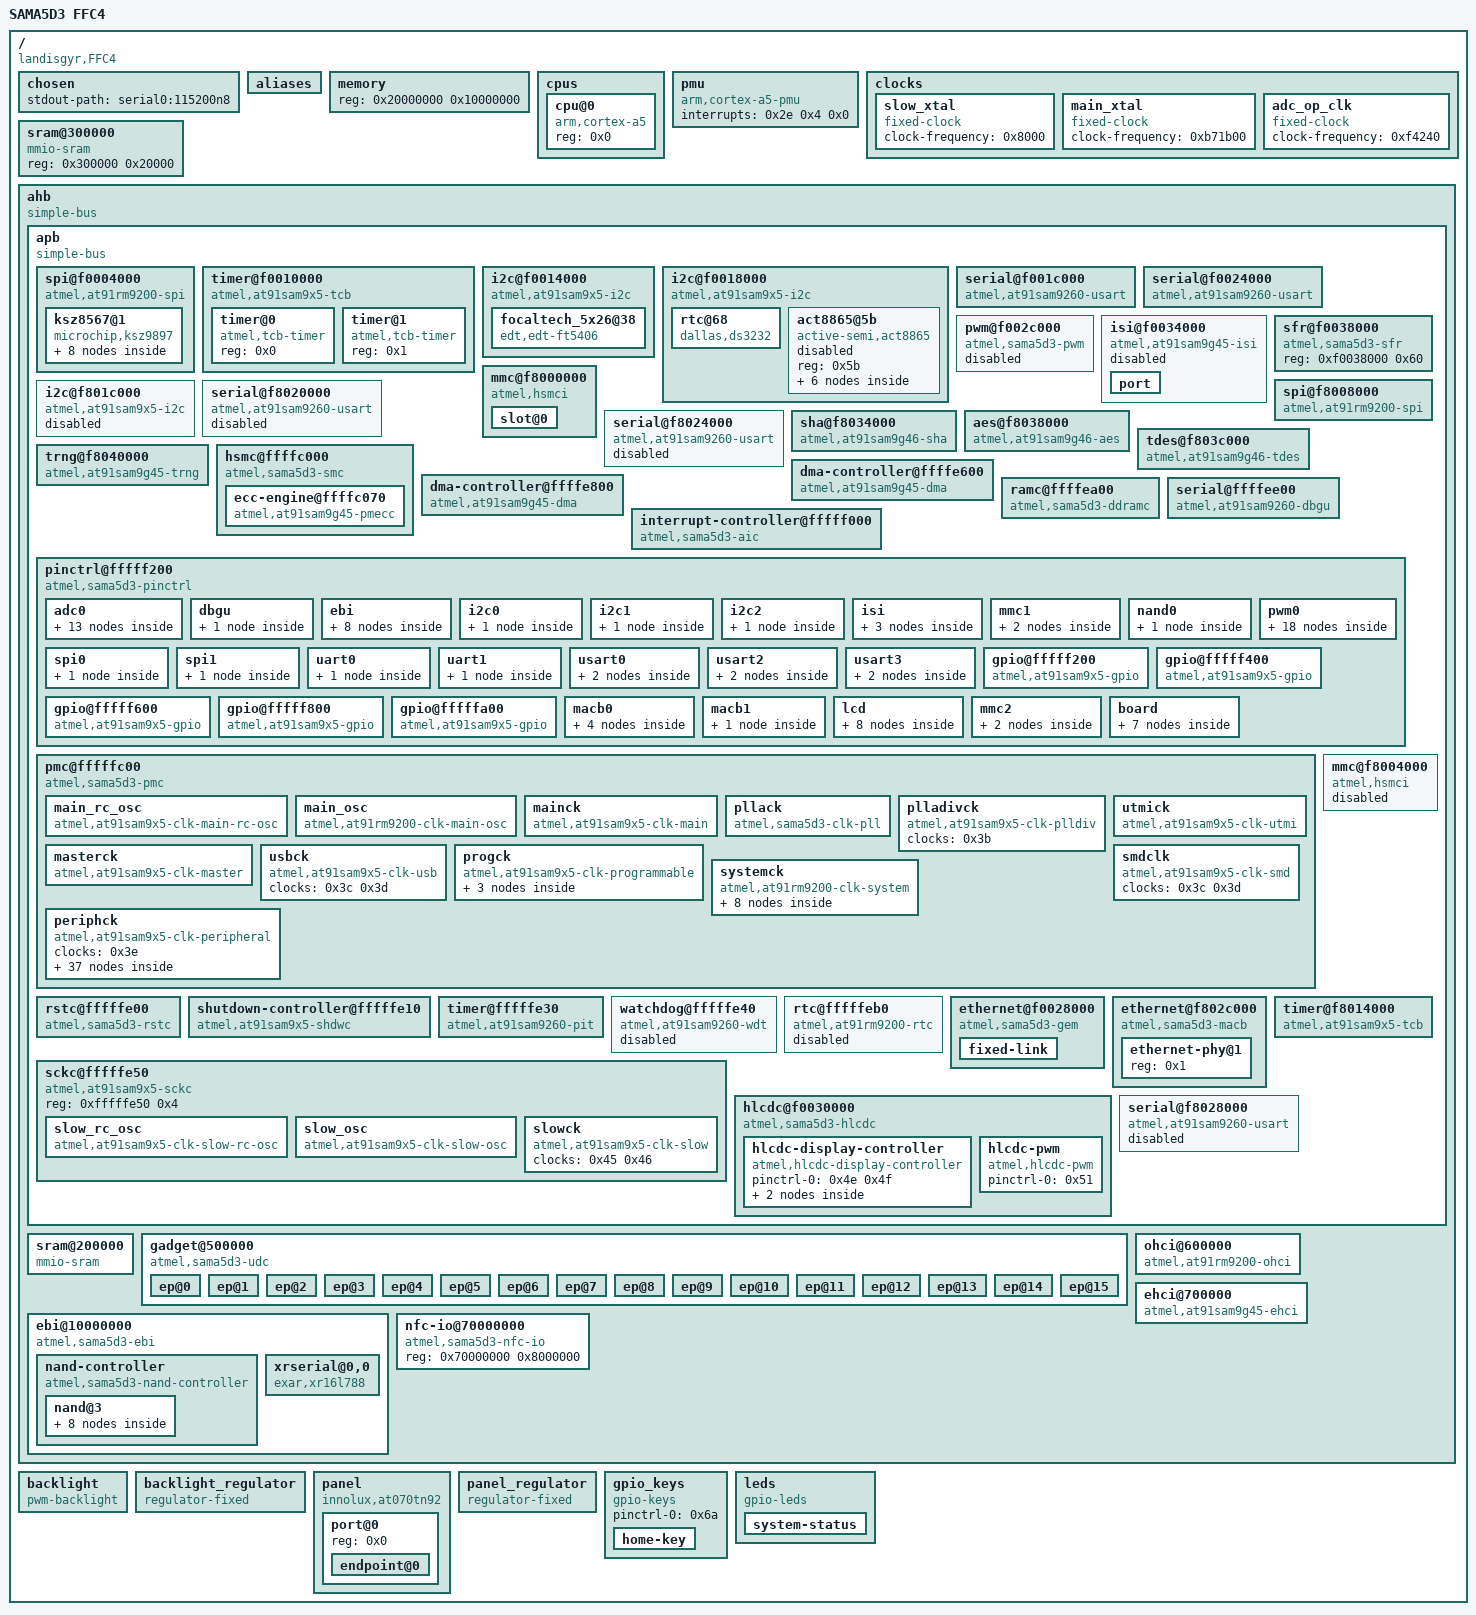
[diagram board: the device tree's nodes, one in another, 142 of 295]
/dts-v1/;

/ {
	#address-cells = <0x1>;
	#size-cells = <0x1>;
	model = "SAMA5D3 FFC4";
	compatible = "landisgyr,FFC4", "atmel,sama5d36", "atmel,sama5d3", "atmel,sama5";
	interrupt-parent = <0x1>;

	chosen {
		stdout-path = "serial0:115200n8";
	};

	aliases {
		serial0 = "/ahb/apb/serial@ffffee00";
		serial1 = "/ahb/apb/serial@f001c000";
		serial3 = "/ahb/apb/serial@f8020000";
		serial4 = "/ahb/apb/serial@f8024000";
		serial5 = "/ahb/apb/serial@f0024000";
		gpio0 = "/ahb/apb/pinctrl@fffff200/gpio@fffff200";
		gpio1 = "/ahb/apb/pinctrl@fffff200/gpio@fffff400";
		gpio2 = "/ahb/apb/pinctrl@fffff200/gpio@fffff600";
		gpio3 = "/ahb/apb/pinctrl@fffff200/gpio@fffff800";
		gpio4 = "/ahb/apb/pinctrl@fffff200/gpio@fffffa00";
		tcb0 = "/ahb/apb/timer@f0010000";
		i2c0 = "/ahb/apb/i2c@f0014000";
		i2c1 = "/ahb/apb/i2c@f0018000";
		i2c2 = "/ahb/apb/i2c@f801c000";
		pwm0 = "/ahb/apb/pwm@f002c000";
		tcb1 = "/ahb/apb/timer@f8014000";
		serial6 = "/ahb/apb/serial@f8028000";
	};

	memory {
		device_type = "memory";
		reg = <0x20000000 0x10000000>;
	};

	cpus {
		#address-cells = <0x1>;
		#size-cells = <0x0>;

		cpu@0 {
			device_type = "cpu";
			compatible = "arm,cortex-a5";
			reg = <0x0>;
		};
	};

	pmu {
		compatible = "arm,cortex-a5-pmu";
		interrupts = <0x2e 0x4 0x0>;
	};

	clocks {

		slow_xtal {
			compatible = "fixed-clock";
			#clock-cells = <0x0>;
			clock-frequency = <0x8000>;
			phandle = <0x44>;
		};

		main_xtal {
			compatible = "fixed-clock";
			#clock-cells = <0x0>;
			clock-frequency = <0xb71b00>;
			phandle = <0x37>;
		};

		adc_op_clk {
			compatible = "fixed-clock";
			#clock-cells = <0x0>;
			clock-frequency = <0xf4240>;
			phandle = <0x6b>;
		};
	};

	sram@300000 {
		compatible = "mmio-sram";
		reg = <0x300000 0x20000>;
		phandle = <0x6c>;
	};

	ahb {
		compatible = "simple-bus";
		#address-cells = <0x1>;
		#size-cells = <0x1>;
		ranges;

		apb {
			compatible = "simple-bus";
			#address-cells = <0x1>;
			#size-cells = <0x1>;
			ranges;

			spi@f0004000 {
				#address-cells = <0x1>;
				#size-cells = <0x0>;
				compatible = "atmel,at91rm9200-spi";
				reg = <0xf0004000 0x100>;
				interrupts = <0x18 0x4 0x3>;
				dmas = <0x2 0x2 0x1 0x2 0x2 0x2>;
				dma-names = "tx", "rx";
				pinctrl-names = "default";
				pinctrl-0 = <0x3>;
				clocks = <0x4>;
				clock-names = "spi_clk";
				status = "okay";
				cs-gpios = <0x5 0xd 0x0 0x5 0xe 0x0>;
				phandle = <0x6d>;

				ksz8567@1 {
					compatible = "microchip,ksz9897";
					reg = <0x1>;
					phy-mode = "rgmii";
					interrupt-parent = <0x6>;
					interrupts = <0xa 0x8>;
					spi-max-frequency = <0x1f78a40>;
					spi-cpha;
					spi-cpol;
					status = "okay";
					phandle = <0x6e>;

					ports {
						#address-cells = <0x1>;
						#size-cells = <0x0>;

						port@0 {
							reg = <0x0>;
							label = "lan1";
						};

						port@1 {
							reg = <0x1>;
							label = "lan2";
						};

						port@2 {
							reg = <0x2>;
							label = "lan3";
						};

						port@3 {
							reg = <0x3>;
							label = "lan4";
						};

						port@4 {
							reg = <0x4>;
							label = "lan5";
						};

						port@5 {
							reg = <0x5>;
							label = "cpu";
							ethernet = <0x7>;

							fixed-link {
								speed = <0x64>;
								full-duplex;
							};
						};
					};
				};
			};

			timer@f0010000 {
				compatible = "atmel,at91sam9x5-tcb", "simple-mfd", "syscon";
				#address-cells = <0x1>;
				#size-cells = <0x0>;
				reg = <0xf0010000 0x100>;
				interrupts = <0x1a 0x4 0x0>;
				clocks = <0x8 0x9>;
				clock-names = "t0_clk", "slow_clk";
				phandle = <0x6f>;

				timer@0 {
					compatible = "atmel,tcb-timer";
					reg = <0x0>;
					phandle = <0x70>;
				};

				timer@1 {
					compatible = "atmel,tcb-timer";
					reg = <0x1>;
					phandle = <0x71>;
				};
			};

			i2c@f0014000 {
				compatible = "atmel,at91sam9x5-i2c";
				reg = <0xf0014000 0x4000>;
				interrupts = <0x12 0x4 0x6>;
				dmas = <0x2 0x2 0x7 0x2 0x2 0x8>;
				dma-names = "tx", "rx";
				pinctrl-names = "default";
				pinctrl-0 = <0xa>;
				#address-cells = <0x1>;
				#size-cells = <0x0>;
				clocks = <0xb>;
				status = "okay";
				phandle = <0x72>;

				focaltech_5x26@38 {
					compatible = "edt,edt-ft5406", "edt,edt-ft5x06";
					reg = <0x38>;
					pinctrl-names = "default";
					pinctrl-0 = <0xc>;
					interrupt-parent = <0x6>;
					interrupts = <0x1d 0x2>;
					touchscreen-size-x = <0x1e0>;
					touchscreen-size-y = <0x320>;
					touchscreen-inverted-y;
					touchscreen-swapped-x-y;
					status = "okay";
				};
			};

			i2c@f0018000 {
				compatible = "atmel,at91sam9x5-i2c";
				reg = <0xf0018000 0x4000>;
				interrupts = <0x13 0x4 0x6>;
				dmas = <0x2 0x2 0x9 0x2 0x2 0xa>;
				dma-names = "tx", "rx";
				pinctrl-names = "default";
				pinctrl-0 = <0xd>;
				#address-cells = <0x1>;
				#size-cells = <0x0>;
				clocks = <0xe>;
				status = "okay";
				phandle = <0x73>;

				rtc@68 {
					compatible = "dallas,ds3232";
					reg = <0x68>;
					interrupt-parent = <0xf>;
					interrupts = <0x18 0x2>;
					status = "okay";
					phandle = <0x74>;
				};

				act8865@5b {
					compatible = "active-semi,act8865";
					reg = <0x5b>;
					status = "disabled";
					phandle = <0x75>;

					regulators {

						DCDC_REG1 {
							regulator-name = "VCC_1V8";
							regulator-min-microvolt = <0x1b7740>;
							regulator-max-microvolt = <0x1b7740>;
							regulator-always-on;
							phandle = <0x76>;
						};

						DCDC_REG2 {
							regulator-name = "VCC_1V2";
							regulator-min-microvolt = <0x124f80>;
							regulator-max-microvolt = <0x124f80>;
							regulator-always-on;
							phandle = <0x77>;
						};

						DCDC_REG3 {
							regulator-name = "VCC_3V3";
							regulator-min-microvolt = <0x325aa0>;
							regulator-max-microvolt = <0x325aa0>;
							regulator-always-on;
							phandle = <0x1c>;
						};

						LDO_REG1 {
							regulator-name = "FUSE_2V5";
							regulator-min-microvolt = <0x2625a0>;
							regulator-max-microvolt = <0x2625a0>;
							phandle = <0x78>;
						};

						LDO_REG2 {
							regulator-name = "VDDANA";
							regulator-min-microvolt = <0x325aa0>;
							regulator-max-microvolt = <0x325aa0>;
							regulator-always-on;
							phandle = <0x79>;
						};
					};
				};
			};

			serial@f001c000 {
				compatible = "atmel,at91sam9260-usart";
				reg = <0xf001c000 0x100>;
				interrupts = <0xc 0x4 0x5>;
				dmas = <0x2 0x2 0x3 0x2 0x2 0x204>;
				dma-names = "tx", "rx";
				pinctrl-names = "default";
				pinctrl-0 = <0x10>;
				clocks = <0x11>;
				clock-names = "usart";
				status = "okay";
				phandle = <0x7a>;
			};

			serial@f0024000 {
				compatible = "atmel,at91sam9260-usart";
				reg = <0xf0024000 0x100>;
				interrupts = <0x10 0x4 0x5>;
				pinctrl-names = "default";
				pinctrl-0 = <0x12>;
				clocks = <0x13>;
				clock-names = "usart";
				status = "okay";
				phandle = <0x7b>;
			};

			pwm@f002c000 {
				compatible = "atmel,sama5d3-pwm";
				reg = <0xf002c000 0x300>;
				interrupts = <0x1c 0x4 0x4>;
				#pwm-cells = <0x3>;
				clocks = <0x14>;
				status = "disabled";
				phandle = <0x7c>;
			};

			isi@f0034000 {
				compatible = "atmel,at91sam9g45-isi";
				reg = <0xf0034000 0x4000>;
				interrupts = <0x25 0x4 0x5>;
				pinctrl-names = "default";
				pinctrl-0 = <0x15>;
				clocks = <0x16>;
				clock-names = "isi_clk";
				status = "disabled";
				phandle = <0x7d>;

				port {
					#address-cells = <0x1>;
					#size-cells = <0x0>;
				};
			};

			sfr@f0038000 {
				compatible = "atmel,sama5d3-sfr", "syscon";
				reg = <0xf0038000 0x60>;
				phandle = <0x7e>;
			};

			mmc@f8000000 {
				compatible = "atmel,hsmci";
				reg = <0xf8000000 0x600>;
				interrupts = <0x16 0x4 0x0>;
				dmas = <0x17 0x2 0x0>;
				dma-names = "rxtx";
				pinctrl-names = "default";
				pinctrl-0 = <0x18 0x19 0x1a>;
				status = "okay";
				#address-cells = <0x1>;
				#size-cells = <0x0>;
				clocks = <0x1b>;
				clock-names = "mci_clk";
				vmmc-supply = <0x1c>;
				vqmmc-supply = <0x1c>;
				phandle = <0x7f>;

				slot@0 {
					reg = <0x0>;
					bus-width = <0x4>;
					cd-gpios = <0x5 0x14 0x0>;
				};
			};

			spi@f8008000 {
				#address-cells = <0x1>;
				#size-cells = <0x0>;
				compatible = "atmel,at91rm9200-spi";
				reg = <0xf8008000 0x100>;
				interrupts = <0x19 0x4 0x3>;
				dmas = <0x17 0x2 0xf 0x17 0x2 0x10>;
				dma-names = "tx", "rx";
				pinctrl-names = "default";
				pinctrl-0 = <0x1d>;
				clocks = <0x1e>;
				clock-names = "spi_clk";
				status = "okay";
				cs-gpios = <0x1f 0x19 0x0>;
				phandle = <0x80>;
			};

			i2c@f801c000 {
				compatible = "atmel,at91sam9x5-i2c";
				reg = <0xf801c000 0x4000>;
				interrupts = <0x14 0x4 0x6>;
				dmas = <0x17 0x2 0xb 0x17 0x2 0xc>;
				dma-names = "tx", "rx";
				pinctrl-names = "default";
				pinctrl-0 = <0x20>;
				#address-cells = <0x1>;
				#size-cells = <0x0>;
				clocks = <0x21>;
				status = "disabled";
				phandle = <0x81>;
			};

			serial@f8020000 {
				compatible = "atmel,at91sam9260-usart";
				reg = <0xf8020000 0x100>;
				interrupts = <0xe 0x4 0x5>;
				dmas = <0x17 0x2 0x7 0x17 0x2 0x208>;
				dma-names = "tx", "rx";
				pinctrl-names = "default";
				pinctrl-0 = <0x22>;
				clocks = <0x23>;
				clock-names = "usart";
				status = "disabled";
				phandle = <0x82>;
			};

			serial@f8024000 {
				compatible = "atmel,at91sam9260-usart";
				reg = <0xf8024000 0x100>;
				interrupts = <0xf 0x4 0x5>;
				dmas = <0x17 0x2 0x9 0x17 0x2 0x20a>;
				dma-names = "tx", "rx";
				pinctrl-names = "default";
				pinctrl-0 = <0x24>;
				clocks = <0x25>;
				clock-names = "usart";
				status = "disabled";
				phandle = <0x83>;
			};

			sha@f8034000 {
				compatible = "atmel,at91sam9g46-sha";
				reg = <0xf8034000 0x100>;
				interrupts = <0x2a 0x4 0x0>;
				dmas = <0x17 0x2 0x11>;
				dma-names = "tx";
				clocks = <0x26>;
				clock-names = "sha_clk";
			};

			aes@f8038000 {
				compatible = "atmel,at91sam9g46-aes";
				reg = <0xf8038000 0x100>;
				interrupts = <0x2b 0x4 0x0>;
				dmas = <0x17 0x2 0x12 0x17 0x2 0x13>;
				dma-names = "tx", "rx";
				clocks = <0x27>;
				clock-names = "aes_clk";
			};

			tdes@f803c000 {
				compatible = "atmel,at91sam9g46-tdes";
				reg = <0xf803c000 0x100>;
				interrupts = <0x2c 0x4 0x0>;
				dmas = <0x17 0x2 0x14 0x17 0x2 0x15>;
				dma-names = "tx", "rx";
				clocks = <0x28>;
				clock-names = "tdes_clk";
			};

			trng@f8040000 {
				compatible = "atmel,at91sam9g45-trng";
				reg = <0xf8040000 0x100>;
				interrupts = <0x2d 0x4 0x0>;
				clocks = <0x29>;
			};

			hsmc@ffffc000 {
				compatible = "atmel,sama5d3-smc", "syscon", "simple-mfd";
				reg = <0xffffc000 0x1000>;
				interrupts = <0x5 0x4 0x6>;
				clocks = <0x2a>;
				#address-cells = <0x1>;
				#size-cells = <0x1>;
				ranges;
				phandle = <0x5c>;

				ecc-engine@ffffc070 {
					compatible = "atmel,at91sam9g45-pmecc";
					reg = <0xffffc070 0x490 0xffffc500 0x100 0xffffc63c 0x14>;
					phandle = <0x63>;
				};
			};

			dma-controller@ffffe600 {
				compatible = "atmel,at91sam9g45-dma";
				reg = <0xffffe600 0x200>;
				interrupts = <0x1e 0x4 0x0>;
				#dma-cells = <0x2>;
				clocks = <0x2b>;
				clock-names = "dma_clk";
				phandle = <0x2>;
			};

			dma-controller@ffffe800 {
				compatible = "atmel,at91sam9g45-dma";
				reg = <0xffffe800 0x200>;
				interrupts = <0x1f 0x4 0x0>;
				#dma-cells = <0x2>;
				clocks = <0x2c>;
				clock-names = "dma_clk";
				phandle = <0x17>;
			};

			ramc@ffffea00 {
				compatible = "atmel,sama5d3-ddramc";
				reg = <0xffffea00 0x200>;
				clocks = <0x2d 0x2e>;
				clock-names = "ddrck", "mpddr";
				phandle = <0x84>;
			};

			serial@ffffee00 {
				compatible = "atmel,at91sam9260-dbgu", "atmel,at91sam9260-usart";
				reg = <0xffffee00 0x200>;
				interrupts = <0x2 0x4 0x7>;
				dmas = <0x17 0x2 0xd 0x17 0x2 0x20e>;
				dma-names = "tx", "rx";
				pinctrl-names = "default";
				pinctrl-0 = <0x2f>;
				clocks = <0x30>;
				clock-names = "usart";
				status = "okay";
				phandle = <0x85>;
			};

			interrupt-controller@fffff000 {
				#interrupt-cells = <0x3>;
				compatible = "atmel,sama5d3-aic";
				interrupt-controller;
				reg = <0xfffff000 0x200>;
				atmel,external-irqs = <0x2f>;
				phandle = <0x1>;
			};

			pinctrl@fffff200 {
				#address-cells = <0x1>;
				#size-cells = <0x1>;
				compatible = "atmel,sama5d3-pinctrl", "atmel,at91sam9x5-pinctrl", "simple-bus";
				ranges = <0xfffff200 0xfffff200 0xa00>;
				atmel,mux-mask = <0xffffffff 0xc0fc0000 0xc0ff0000 0xffffffff 0xff8ffff 0x0 0xffffffff 0xbc00f1ff 0x7c00fc00 0xffffffff 0xc001c0e0 0x1c1e0 0xffffffff 0xbf9f8000 0x18000000>;
				phandle = <0x86>;

				adc0 {

					adc0_adtrg {
						atmel,pins = <0x3 0x13 0x1 0x0>;
						phandle = <0x87>;
					};

					adc0_ad0 {
						atmel,pins = <0x3 0x14 0x1 0x0>;
						phandle = <0x88>;
					};

					adc0_ad1 {
						atmel,pins = <0x3 0x15 0x1 0x0>;
						phandle = <0x89>;
					};

					adc0_ad2 {
						atmel,pins = <0x3 0x16 0x1 0x0>;
						phandle = <0x8a>;
					};

					adc0_ad3 {
						atmel,pins = <0x3 0x17 0x1 0x0>;
						phandle = <0x8b>;
					};

					adc0_ad4 {
						atmel,pins = <0x3 0x18 0x1 0x0>;
						phandle = <0x8c>;
					};

					adc0_ad5 {
						atmel,pins = <0x3 0x19 0x1 0x0>;
						phandle = <0x8d>;
					};

					adc0_ad6 {
						atmel,pins = <0x3 0x1a 0x1 0x0>;
						phandle = <0x8e>;
					};

					adc0_ad7 {
						atmel,pins = <0x3 0x1b 0x1 0x0>;
						phandle = <0x8f>;
					};

					adc0_ad8 {
						atmel,pins = <0x3 0x1c 0x1 0x0>;
						phandle = <0x90>;
					};

					adc0_ad9 {
						atmel,pins = <0x3 0x1d 0x1 0x0>;
						phandle = <0x91>;
					};

					adc0_ad10 {
						atmel,pins = <0x3 0x1e 0x1 0x0>;
						phandle = <0x92>;
					};

					adc0_ad11 {
						atmel,pins = <0x3 0x1f 0x1 0x0>;
						phandle = <0x93>;
					};
				};

				dbgu {

					dbgu-0 {
						atmel,pins = <0x1 0x1e 0x1 0x1 0x1 0x1f 0x1 0x0>;
						phandle = <0x2f>;
					};
				};

				ebi {

					ebi-addr-0 {
						atmel,pins = <0x4 0x1 0x1 0x0 0x4 0x2 0x1 0x0 0x4 0x3 0x1 0x0 0x4 0x4 0x1 0x0 0x4 0x5 0x1 0x0 0x4 0x6 0x1 0x0 0x4 0x7 0x1 0x0 0x4 0x8 0x1 0x0 0x4 0x9 0x1 0x0 0x4 0xa 0x1 0x0 0x4 0xb 0x1 0x0 0x4 0xc 0x1 0x0 0x4 0xd 0x1 0x0 0x4 0xe 0x1 0x0 0x4 0xf 0x1 0x0 0x4 0x10 0x1 0x0 0x4 0x11 0x1 0x0 0x4 0x12 0x1 0x0 0x4 0x13 0x1 0x0 0x4 0x14 0x1 0x0 0x4 0x15 0x1 0x0 0x4 0x16 0x1 0x0 0x4 0x17 0x1 0x0>;
						phandle = <0x94>;
					};

					ebi-addr-1 {
						atmel,pins = <0x4 0x15 0x1 0x0 0x4 0x16 0x1 0x0>;
						phandle = <0x64>;
					};

					ebi-addr-2 {
						atmel,pins = <0x4 0x1 0x1 0x0 0x4 0x2 0x1 0x0 0x4 0x3 0x1 0x0 0x4 0x4 0x1 0x0 0x4 0x5 0x1 0x0 0x4 0x6 0x1 0x0 0x4 0x7 0x1 0x0 0x4 0x8 0x1 0x0 0x4 0x9 0x1 0x0 0x4 0xa 0x1 0x0 0x4 0xb 0x1 0x0 0x4 0xc 0x1 0x0 0x4 0xd 0x1 0x0 0x4 0xe 0x1 0x0 0x4 0xf 0x1 0x0 0x4 0x10 0x1 0x0>;
						phandle = <0x5d>;
					};

					ebi-cs0-0 {
						atmel,pins = <0x4 0x18 0x1 0x0>;
						phandle = <0x5e>;
					};

					ebi-cs1-0 {
						atmel,pins = <0x4 0x19 0x1 0x0>;
						phandle = <0x5f>;
					};

					ebi-cs2-0 {
						atmel,pins = <0x4 0x1a 0x1 0x0>;
						phandle = <0x60>;
					};

					ebi-nwait-0 {
						atmel,pins = <0x4 0x1c 0x1 0x0>;
						phandle = <0x95>;
					};

					ebi-nwr1-nbs1-0 {
						atmel,pins = <0x4 0x1b 0x1 0x0>;
						phandle = <0x96>;
					};
				};

				i2c0 {

					i2c0-0 {
						atmel,pins = <0x0 0x1e 0x1 0x0 0x0 0x1f 0x1 0x0>;
						phandle = <0x97>;
					};
				};

				i2c1 {

					i2c1-0 {
						atmel,pins = <0x2 0x1a 0x2 0x0 0x2 0x1b 0x2 0x0>;
						phandle = <0x98>;
					};
				};

				i2c2 {

					i2c2-0 {
						atmel,pins = <0x0 0x12 0x2 0x0 0x0 0x13 0x2 0x0>;
						phandle = <0x20>;
					};
				};

				isi {

					isi-0-data-0-7 {
						atmel,pins = <0x0 0x10 0x3 0x0 0x0 0x11 0x3 0x0 0x0 0x12 0x3 0x0 0x0 0x13 0x3 0x0 0x0 0x14 0x3 0x0 0x0 0x15 0x3 0x0 0x0 0x16 0x3 0x0 0x0 0x17 0x3 0x0 0x2 0x1e 0x3 0x0 0x0 0x1f 0x3 0x0 0x0 0x1e 0x3 0x0>;
						phandle = <0x15>;
					};

					isi-0-data-8-9 {
						atmel,pins = <0x2 0x1d 0x3 0x0 0x2 0x1c 0x3 0x0>;
						phandle = <0x99>;
					};

					isi-0-data-10-11 {
						atmel,pins = <0x2 0x1b 0x3 0x0 0x2 0x1a 0x3 0x0>;
						phandle = <0x9a>;
					};
				};

				mmc1 {

					mmc1_clk_cmd_dat0 {
						atmel,pins = <0x1 0x18 0x1 0x0 0x1 0x13 0x1 0x1 0x1 0x14 0x1 0x1>;
						phandle = <0x18>;
					};

					mmc1_dat1_3 {
						atmel,pins = <0x1 0x15 0x1 0x1 0x1 0x16 0x1 0x1 0x1 0x17 0x1 0x1>;
						phandle = <0x19>;
					};
				};

				nand0 {

					nand0_ale_cle-0 {
						atmel,pins = <0x4 0x15 0x1 0x1 0x4 0x16 0x1 0x1>;
						phandle = <0x9b>;
					};
				};

				pwm0 {

					pwm0_pwmh0-0 {
						atmel,pins = <0x0 0x14 0x2 0x0>;
						phandle = <0x9c>;
					};

					pwm0_pwmh0-1 {
						atmel,pins = <0x1 0x0 0x2 0x0>;
						phandle = <0x9d>;
					};

					pwm0_pwml0-0 {
						atmel,pins = <0x0 0x15 0x2 0x0>;
						phandle = <0x9e>;
					};

					pwm0_pwml0-1 {
						atmel,pins = <0x1 0x1 0x2 0x0>;
						phandle = <0x9f>;
					};

					pwm0_pwmh1-0 {
						atmel,pins = <0x0 0x16 0x2 0x0>;
						phandle = <0xa0>;
					};

					pwm0_pwmh1-1 {
						atmel,pins = <0x1 0x4 0x2 0x0>;
						phandle = <0xa1>;
					};

					pwm0_pwmh1-2 {
						atmel,pins = <0x1 0x1b 0x3 0x0>;
						phandle = <0xa2>;
					};

					pwm0_pwml1-0 {
						atmel,pins = <0x0 0x17 0x2 0x0>;
						phandle = <0xa3>;
					};

					pwm0_pwml1-1 {
						atmel,pins = <0x1 0x5 0x2 0x0>;
						phandle = <0xa4>;
					};

					pwm0_pwml1-2 {
						atmel,pins = <0x4 0x1f 0x2 0x0>;
						phandle = <0xa5>;
					};

					pwm0_pwmh2-0 {
						atmel,pins = <0x1 0x8 0x2 0x0>;
						phandle = <0xa6>;
					};

					pwm0_pwmh2-1 {
						atmel,pins = <0x3 0x5 0x3 0x0>;
						phandle = <0xa7>;
					};

					pwm0_pwml2-0 {
						atmel,pins = <0x1 0x9 0x2 0x0>;
						phandle = <0xa8>;
					};

					pwm0_pwml2-1 {
						atmel,pins = <0x3 0x6 0x3 0x0>;
						phandle = <0xa9>;
					};

					pwm0_pwmh3-0 {
						atmel,pins = <0x1 0xc 0x2 0x0>;
						phandle = <0xaa>;
					};

					pwm0_pwmh3-1 {
						atmel,pins = <0x3 0x7 0x3 0x0>;
						phandle = <0xab>;
					};

					pwm0_pwml3-0 {
						atmel,pins = <0x1 0xd 0x2 0x0>;
						phandle = <0xac>;
					};

					pwm0_pwml3-1 {
						atmel,pins = <0x3 0x8 0x3 0x0>;
						phandle = <0xad>;
					};
				};

				spi0 {

					spi0-0 {
						atmel,pins = <0x3 0xa 0x1 0x0 0x3 0xb 0x1 0x0 0x3 0xc 0x1 0x0>;
						phandle = <0x3>;
					};
				};

				spi1 {

					spi1-0 {
						atmel,pins = <0x2 0x16 0x1 0x0 0x2 0x17 0x1 0x0 0x2 0x18 0x1 0x0>;
						phandle = <0x1d>;
					};
				};

				uart0 {

					uart0-0 {
						atmel,pins = <0x2 0x1d 0x1 0x1 0x2 0x1e 0x1 0x0>;
						phandle = <0x12>;
					};
				};

				uart1 {

					uart1-0 {
						atmel,pins = <0x0 0x1e 0x2 0x1 0x0 0x1f 0x2 0x0>;
						phandle = <0x56>;
					};
				};

				usart0 {

					usart0-0 {
						atmel,pins = <0x3 0x11 0x1 0x1 0x3 0x12 0x1 0x0>;
						phandle = <0x10>;
					};

					usart0_rts_cts-0 {
						atmel,pins = <0x3 0xf 0x1 0x0 0x3 0x10 0x1 0x0>;
						phandle = <0xae>;
					};
				};

				usart2 {

					usart2-0 {
						atmel,pins = <0x4 0x19 0x2 0x1 0x4 0x1a 0x2 0x0>;
						phandle = <0x22>;
					};

					usart2_rts_cts-0 {
						atmel,pins = <0x4 0x17 0x2 0x0 0x4 0x18 0x2 0x0>;
						phandle = <0xaf>;
					};
				};

				usart3 {

					usart3-0 {
						atmel,pins = <0x4 0x12 0x2 0x1 0x4 0x13 0x2 0x0>;
						phandle = <0x24>;
					};

					usart3_rts_cts-0 {
						atmel,pins = <0x4 0x10 0x2 0x0 0x4 0x11 0x2 0x0>;
						phandle = <0xb0>;
					};
				};

				gpio@fffff200 {
					compatible = "atmel,at91sam9x5-gpio", "atmel,at91rm9200-gpio";
					reg = <0xfffff200 0x100>;
					interrupts = <0x6 0x4 0x1>;
					#gpio-cells = <0x2>;
					gpio-controller;
					interrupt-controller;
					#interrupt-cells = <0x2>;
					clocks = <0x31>;
					phandle = <0xb1>;
				};

				gpio@fffff400 {
					compatible = "atmel,at91sam9x5-gpio", "atmel,at91rm9200-gpio";
					reg = <0xfffff400 0x100>;
					interrupts = <0x7 0x4 0x1>;
					#gpio-cells = <0x2>;
					gpio-controller;
					interrupt-controller;
					#interrupt-cells = <0x2>;
					clocks = <0x32>;
					phandle = <0x6>;
				};

				gpio@fffff600 {
					compatible = "atmel,at91sam9x5-gpio", "atmel,at91rm9200-gpio";
					reg = <0xfffff600 0x100>;
					interrupts = <0x8 0x4 0x1>;
					#gpio-cells = <0x2>;
					gpio-controller;
					interrupt-controller;
					#interrupt-cells = <0x2>;
					clocks = <0x33>;
					phandle = <0x1f>;
				};

				gpio@fffff800 {
					compatible = "atmel,at91sam9x5-gpio", "atmel,at91rm9200-gpio";
					reg = <0xfffff800 0x100>;
					interrupts = <0x9 0x4 0x1>;
					#gpio-cells = <0x2>;
					gpio-controller;
					interrupt-controller;
					#interrupt-cells = <0x2>;
					clocks = <0x34>;
					phandle = <0x5>;
				};

				gpio@fffffa00 {
					compatible = "atmel,at91sam9x5-gpio", "atmel,at91rm9200-gpio";
					reg = <0xfffffa00 0x100>;
					interrupts = <0xa 0x4 0x1>;
					#gpio-cells = <0x2>;
					gpio-controller;
					interrupt-controller;
					#interrupt-cells = <0x2>;
					clocks = <0x35>;
					phandle = <0xf>;
				};

				macb0 {

					macb0_data_rgmii {
						atmel,pins = <0x1 0x0 0x1 0x0 0x1 0x1 0x1 0x0 0x1 0x2 0x1 0x0 0x1 0x3 0x1 0x0 0x1 0x4 0x1 0x0 0x1 0x5 0x1 0x0 0x1 0x6 0x1 0x0 0x1 0x7 0x1 0x0>;
						phandle = <0x47>;
					};

					macb0_data_gmii {
						atmel,pins = <0x1 0x13 0x2 0x0 0x1 0x14 0x2 0x0 0x1 0x15 0x2 0x0 0x1 0x16 0x2 0x0 0x1 0x17 0x2 0x0 0x1 0x18 0x2 0x0 0x1 0x19 0x2 0x0 0x1 0x1a 0x2 0x0>;
						phandle = <0xb2>;
					};

					macb0_signal_rgmii {
						atmel,pins = <0x1 0x8 0x1 0x0 0x1 0x9 0x1 0x0 0x1 0xb 0x1 0x0 0x1 0xd 0x1 0x0 0x1 0x10 0x1 0x0 0x1 0x11 0x1 0x0 0x1 0x12 0x1 0x0>;
						phandle = <0x48>;
					};

					macb0_signal_gmii {
						atmel,pins = <0x1 0x9 0x1 0x0 0x1 0xa 0x1 0x0 0x1 0xb 0x1 0x0 0x1 0xc 0x1 0x0 0x1 0xd 0x1 0x0 0x1 0xe 0x1 0x0 0x1 0xf 0x1 0x0 0x1 0x10 0x1 0x0 0x1 0x11 0x1 0x0 0x1 0x1b 0x2 0x0>;
						phandle = <0xb3>;
					};
				};

				macb1 {

					macb1_rmii-0 {
						atmel,pins = <0x2 0x0 0x1 0x0 0x2 0x1 0x1 0x0 0x2 0x2 0x1 0x0 0x2 0x3 0x1 0x0 0x2 0x4 0x1 0x0 0x2 0x5 0x1 0x0 0x2 0x6 0x1 0x0 0x2 0x7 0x1 0x0 0x2 0x8 0x1 0x0 0x2 0x9 0x1 0x0>;
						phandle = <0x4a>;
					};
				};

				lcd {

					lcd-base-0 {
						atmel,pins = <0x0 0x1a 0x1 0x0 0x0 0x1b 0x1 0x0 0x0 0x19 0x1 0x0 0x0 0x1d 0x1 0x0 0x0 0x1c 0x1 0x0>;
						phandle = <0x4e>;
					};

					lcd-pwm-0 {
						atmel,pins = <0x0 0x18 0x1 0x0>;
						phandle = <0x51>;
					};

					lcd-rgb-0 {
						atmel,pins = <0x0 0x0 0x1 0x0 0x0 0x1 0x1 0x0 0x0 0x2 0x1 0x0 0x0 0x3 0x1 0x0 0x0 0x4 0x1 0x0 0x0 0x5 0x1 0x0 0x0 0x6 0x1 0x0 0x0 0x7 0x1 0x0 0x0 0x8 0x1 0x0 0x0 0x9 0x1 0x0 0x0 0xa 0x1 0x0 0x0 0xb 0x1 0x0>;
						phandle = <0xb4>;
					};

					lcd-rgb-1 {
						atmel,pins = <0x0 0x0 0x1 0x0 0x0 0x1 0x1 0x0 0x0 0x2 0x1 0x0 0x0 0x3 0x1 0x0 0x0 0x4 0x1 0x0 0x0 0x5 0x1 0x0 0x0 0x6 0x1 0x0 0x0 0x7 0x1 0x0 0x0 0x8 0x1 0x0 0x0 0x9 0x1 0x0 0x0 0xa 0x1 0x0 0x0 0xb 0x1 0x0 0x0 0xc 0x1 0x0 0x0 0xd 0x1 0x0 0x0 0xe 0x1 0x0 0x0 0xf 0x1 0x0>;
						phandle = <0xb5>;
					};

					lcd-rgb-2 {
						atmel,pins = <0x0 0x0 0x1 0x0 0x0 0x1 0x1 0x0 0x0 0x2 0x1 0x0 0x0 0x3 0x1 0x0 0x0 0x4 0x1 0x0 0x0 0x5 0x1 0x0 0x0 0x6 0x1 0x0 0x0 0x7 0x1 0x0 0x0 0x8 0x1 0x0 0x0 0x9 0x1 0x0 0x0 0xa 0x1 0x0 0x0 0xb 0x1 0x0 0x0 0xc 0x1 0x0 0x0 0xd 0x1 0x0 0x0 0xe 0x1 0x0 0x0 0xf 0x1 0x0 0x0 0x10 0x1 0x0 0x0 0x11 0x1 0x0>;
						phandle = <0xb6>;
					};

					lcd-rgb-2-alt {
						atmel,pins = <0x0 0x0 0x1 0x0 0x0 0x1 0x1 0x0 0x0 0x2 0x1 0x0 0x0 0x3 0x1 0x0 0x0 0x4 0x1 0x0 0x0 0x5 0x1 0x0 0x0 0x6 0x1 0x0 0x0 0x7 0x1 0x0 0x0 0x8 0x1 0x0 0x0 0x9 0x1 0x0 0x0 0xa 0x1 0x0 0x0 0xb 0x1 0x0 0x0 0xc 0x1 0x0 0x0 0xd 0x1 0x0 0x0 0xe 0x1 0x0 0x0 0xf 0x1 0x0 0x2 0xe 0x3 0x0 0x2 0xd 0x3 0x0>;
						phandle = <0xb7>;
					};

					lcd-rgb-3 {
						atmel,pins = <0x0 0x0 0x1 0x0 0x0 0x1 0x1 0x0 0x0 0x2 0x1 0x0 0x0 0x3 0x1 0x0 0x0 0x4 0x1 0x0 0x0 0x5 0x1 0x0 0x0 0x6 0x1 0x0 0x0 0x7 0x1 0x0 0x0 0x8 0x1 0x0 0x0 0x9 0x1 0x0 0x0 0xa 0x1 0x0 0x0 0xb 0x1 0x0 0x0 0xc 0x1 0x0 0x0 0xd 0x1 0x0 0x0 0xe 0x1 0x0 0x0 0xf 0x1 0x0 0x0 0x10 0x1 0x0 0x0 0x11 0x1 0x0 0x0 0x12 0x1 0x0 0x0 0x13 0x1 0x0 0x0 0x14 0x1 0x0 0x0 0x15 0x1 0x0 0x0 0x16 0x1 0x0 0x0 0x17 0x1 0x0>;
						phandle = <0x4f>;
					};

					lcd-rgb-3-alt {
						atmel,pins = <0x0 0x0 0x1 0x0 0x0 0x1 0x1 0x0 0x0 0x2 0x1 0x0 0x0 0x3 0x1 0x0 0x0 0x4 0x1 0x0 0x0 0x5 0x1 0x0 0x0 0x6 0x1 0x0 0x0 0x7 0x1 0x0 0x0 0x8 0x1 0x0 0x0 0x9 0x1 0x0 0x0 0xa 0x1 0x0 0x0 0xb 0x1 0x0 0x0 0xc 0x1 0x0 0x0 0xd 0x1 0x0 0x0 0xe 0x1 0x0 0x0 0xf 0x1 0x0 0x2 0xe 0x3 0x0 0x2 0xd 0x3 0x0 0x2 0xc 0x3 0x0 0x2 0xb 0x3 0x0 0x2 0xa 0x3 0x0 0x2 0xf 0x3 0x0 0x4 0x1b 0x3 0x0 0x4 0x1c 0x3 0x0>;
						phandle = <0xb8>;
					};
				};

				mmc2 {

					mmc2_clk_cmd_dat0 {
						atmel,pins = <0x2 0xf 0x1 0x0 0x2 0xa 0x1 0x1 0x2 0xb 0x1 0x1>;
						phandle = <0x52>;
					};

					mmc2_dat1_3 {
						atmel,pins = <0x2 0xc 0x1 0x1 0x2 0xd 0x1 0x1 0x2 0xe 0x1 0x1>;
						phandle = <0x53>;
					};
				};

				board {

					lcd_ctp_int {
						atmel,pins = <0x1 0x1d 0x0 0x5>;
						phandle = <0xc>;
					};

					i2c0_pu {
						atmel,pins = <0x0 0x1e 0x1 0x1 0x0 0x1f 0x1 0x1>;
						phandle = <0xa>;
					};

					i2c1_pu {
						atmel,pins = <0x2 0x1a 0x2 0x0 0x2 0x1b 0x2 0x0>;
						phandle = <0xd>;
					};

					i2c2_pu {
						atmel,pins = <0x0 0x12 0x2 0x1 0x0 0x13 0x2 0x1>;
						phandle = <0xb9>;
					};

					key_gpio_0 {
						atmel,pins = <0x1 0x19 0x0 0x5>;
						phandle = <0x6a>;
					};

					mmc1_cd {
						atmel,pins = <0x3 0x14 0x0 0x5>;
						phandle = <0x1a>;
					};

					usba_vbus {
						atmel,pins = <0x4 0x9 0x0 0x4>;
						phandle = <0x59>;
					};
				};
			};

			pmc@fffffc00 {
				compatible = "atmel,sama5d3-pmc", "syscon";
				reg = <0xfffffc00 0x120>;
				interrupts = <0x1 0x4 0x7>;
				interrupt-controller;
				#address-cells = <0x1>;
				#size-cells = <0x0>;
				#interrupt-cells = <0x1>;
				phandle = <0x36>;

				main_rc_osc {
					compatible = "atmel,at91sam9x5-clk-main-rc-osc";
					#clock-cells = <0x0>;
					interrupt-parent = <0x36>;
					interrupts = <0x11>;
					clock-frequency = <0xb71b00>;
					clock-accuracy = <0x2faf080>;
					phandle = <0x38>;
				};

				main_osc {
					compatible = "atmel,at91rm9200-clk-main-osc";
					#clock-cells = <0x0>;
					interrupt-parent = <0x36>;
					interrupts = <0x0>;
					clocks = <0x37>;
					phandle = <0x39>;
				};

				mainck {
					compatible = "atmel,at91sam9x5-clk-main";
					#clock-cells = <0x0>;
					interrupt-parent = <0x36>;
					interrupts = <0x10>;
					clocks = <0x38 0x39>;
					phandle = <0x3a>;
				};

				pllack {
					compatible = "atmel,sama5d3-clk-pll";
					#clock-cells = <0x0>;
					interrupt-parent = <0x36>;
					interrupts = <0x1>;
					clocks = <0x3a>;
					reg = <0x0>;
					atmel,clk-input-range = <0x7a1200 0x2faf080>;
					#atmel,pll-clk-output-range-cells = <0x4>;
					atmel,pll-clk-output-ranges = <0x17d78400 0x3b9aca00 0x0 0x0>;
					phandle = <0x3b>;
				};

				plladivck {
					compatible = "atmel,at91sam9x5-clk-plldiv";
					#clock-cells = <0x0>;
					clocks = <0x3b>;
					phandle = <0x3c>;
				};

				utmick {
					compatible = "atmel,at91sam9x5-clk-utmi";
					#clock-cells = <0x0>;
					interrupt-parent = <0x36>;
					interrupts = <0x6>;
					clocks = <0x3a>;
					phandle = <0x3d>;
				};

				masterck {
					compatible = "atmel,at91sam9x5-clk-master";
					#clock-cells = <0x0>;
					interrupt-parent = <0x36>;
					interrupts = <0x3>;
					clocks = <0x9 0x3a 0x3c 0x3d>;
					atmel,clk-output-range = <0x0 0x9e4f580>;
					atmel,clk-divisors = <0x1 0x2 0x4 0x3>;
					phandle = <0x3e>;
				};

				usbck {
					compatible = "atmel,at91sam9x5-clk-usb";
					#clock-cells = <0x0>;
					clocks = <0x3c 0x3d>;
					phandle = <0x40>;
				};

				progck {
					compatible = "atmel,at91sam9x5-clk-programmable";
					#address-cells = <0x1>;
					#size-cells = <0x0>;
					interrupt-parent = <0x36>;
					clocks = <0x9 0x3a 0x3c 0x3d 0x3e>;
					phandle = <0xba>;

					prog0 {
						#clock-cells = <0x0>;
						reg = <0x0>;
						interrupts = <0x8>;
						phandle = <0x41>;
					};

					prog1 {
						#clock-cells = <0x0>;
						reg = <0x1>;
						interrupts = <0x9>;
						phandle = <0x42>;
					};

					prog2 {
						#clock-cells = <0x0>;
						reg = <0x2>;
						interrupts = <0xa>;
						phandle = <0x43>;
					};
				};

				smdclk {
					compatible = "atmel,at91sam9x5-clk-smd";
					#clock-cells = <0x0>;
					clocks = <0x3c 0x3d>;
					phandle = <0x3f>;
				};

				systemck {
					compatible = "atmel,at91rm9200-clk-system";
					#address-cells = <0x1>;
					#size-cells = <0x0>;

					ddrck {
						#clock-cells = <0x0>;
						reg = <0x2>;
						clocks = <0x3e>;
						phandle = <0x2d>;
					};

					smdck {
						#clock-cells = <0x0>;
						reg = <0x4>;
						clocks = <0x3f>;
						phandle = <0xbb>;
					};

					uhpck {
						#clock-cells = <0x0>;
						reg = <0x6>;
						clocks = <0x40>;
						phandle = <0x5b>;
					};

					udpck {
						#clock-cells = <0x0>;
						reg = <0x7>;
						clocks = <0x40>;
						phandle = <0xbc>;
					};

					pck0 {
						#clock-cells = <0x0>;
						reg = <0x8>;
						clocks = <0x41>;
						phandle = <0xbd>;
					};

					pck1 {
						#clock-cells = <0x0>;
						reg = <0x9>;
						clocks = <0x42>;
						phandle = <0xbe>;
					};

					pck2 {
						#clock-cells = <0x0>;
						reg = <0xa>;
						clocks = <0x43>;
						phandle = <0xbf>;
					};

					lcdck {
						#clock-cells = <0x0>;
						reg = <0x3>;
						clocks = <0x3e>;
						phandle = <0x4d>;
					};
				};

				periphck {
					compatible = "atmel,at91sam9x5-clk-peripheral";
					#address-cells = <0x1>;
					#size-cells = <0x0>;
					clocks = <0x3e>;

					dbgu_clk {
						#clock-cells = <0x0>;
						reg = <0x2>;
						phandle = <0x30>;
					};

					hsmc_clk {
						#clock-cells = <0x0>;
						reg = <0x5>;
						phandle = <0x2a>;
					};

					pioA_clk {
						#clock-cells = <0x0>;
						reg = <0x6>;
						phandle = <0x31>;
					};

					pioB_clk {
						#clock-cells = <0x0>;
						reg = <0x7>;
						phandle = <0x32>;
					};

					pioC_clk {
						#clock-cells = <0x0>;
						reg = <0x8>;
						phandle = <0x33>;
					};

					pioD_clk {
						#clock-cells = <0x0>;
						reg = <0x9>;
						phandle = <0x34>;
					};

					pioE_clk {
						#clock-cells = <0x0>;
						reg = <0xa>;
						phandle = <0x35>;
					};

					usart0_clk {
						#clock-cells = <0x0>;
						reg = <0xc>;
						atmel,clk-output-range = <0x0 0x3ef1480>;
						phandle = <0x11>;
					};

					usart2_clk {
						#clock-cells = <0x0>;
						reg = <0xe>;
						atmel,clk-output-range = <0x0 0x3ef1480>;
						phandle = <0x23>;
					};

					usart3_clk {
						#clock-cells = <0x0>;
						reg = <0xf>;
						atmel,clk-output-range = <0x0 0x3ef1480>;
						phandle = <0x25>;
					};

					uart0_clk {
						#clock-cells = <0x0>;
						reg = <0x10>;
						atmel,clk-output-range = <0x0 0x3ef1480>;
						phandle = <0x13>;
					};

					twi0_clk {
						reg = <0x12>;
						#clock-cells = <0x0>;
						atmel,clk-output-range = <0x0 0xfdad68>;
						phandle = <0xb>;
					};

					twi1_clk {
						#clock-cells = <0x0>;
						reg = <0x13>;
						atmel,clk-output-range = <0x0 0xfdad68>;
						phandle = <0xe>;
					};

					twi2_clk {
						#clock-cells = <0x0>;
						reg = <0x14>;
						atmel,clk-output-range = <0x0 0xfdad68>;
						phandle = <0x21>;
					};

					mci1_clk {
						#clock-cells = <0x0>;
						reg = <0x16>;
						phandle = <0x1b>;
					};

					spi0_clk {
						#clock-cells = <0x0>;
						reg = <0x18>;
						atmel,clk-output-range = <0x0 0x7ed6b40>;
						phandle = <0x4>;
					};

					spi1_clk {
						#clock-cells = <0x0>;
						reg = <0x19>;
						atmel,clk-output-range = <0x0 0x7ed6b40>;
						phandle = <0x1e>;
					};

					tcb0_clk {
						#clock-cells = <0x0>;
						reg = <0x1a>;
						atmel,clk-output-range = <0x0 0x7ed6b40>;
						phandle = <0x8>;
					};

					pwm_clk {
						#clock-cells = <0x0>;
						reg = <0x1c>;
						phandle = <0x14>;
					};

					adc_clk {
						#clock-cells = <0x0>;
						reg = <0x1d>;
						atmel,clk-output-range = <0x0 0x3ef1480>;
						phandle = <0xc0>;
					};

					dma0_clk {
						#clock-cells = <0x0>;
						reg = <0x1e>;
						phandle = <0x2b>;
					};

					dma1_clk {
						#clock-cells = <0x0>;
						reg = <0x1f>;
						phandle = <0x2c>;
					};

					uhphs_clk {
						#clock-cells = <0x0>;
						reg = <0x20>;
						phandle = <0x5a>;
					};

					udphs_clk {
						#clock-cells = <0x0>;
						reg = <0x21>;
						phandle = <0x58>;
					};

					isi_clk {
						#clock-cells = <0x0>;
						reg = <0x25>;
						phandle = <0x16>;
					};

					sha_clk {
						#clock-cells = <0x0>;
						reg = <0x2a>;
						phandle = <0x26>;
					};

					aes_clk {
						#clock-cells = <0x0>;
						reg = <0x2b>;
						phandle = <0x27>;
					};

					tdes_clk {
						#clock-cells = <0x0>;
						reg = <0x2c>;
						phandle = <0x28>;
					};

					trng_clk {
						#clock-cells = <0x0>;
						reg = <0x2d>;
						phandle = <0x29>;
					};

					fuse_clk {
						#clock-cells = <0x0>;
						reg = <0x30>;
						phandle = <0xc1>;
					};

					mpddr_clk {
						#clock-cells = <0x0>;
						reg = <0x31>;
						phandle = <0x2e>;
					};

					macb0_clk {
						#clock-cells = <0x0>;
						reg = <0x22>;
						phandle = <0x49>;
					};

					macb1_clk {
						#clock-cells = <0x0>;
						reg = <0x23>;
						phandle = <0x4b>;
					};

					lcdc_clk {
						#clock-cells = <0x0>;
						reg = <0x24>;
						phandle = <0x4c>;
					};

					mci2_clk {
						#clock-cells = <0x0>;
						reg = <0x17>;
						phandle = <0x54>;
					};

					tcb1_clk {
						#clock-cells = <0x0>;
						reg = <0x1b>;
						phandle = <0x55>;
					};

					uart1_clk {
						#clock-cells = <0x0>;
						reg = <0x11>;
						atmel,clk-output-range = <0x0 0x3ef1480>;
						phandle = <0x57>;
					};
				};
			};

			rstc@fffffe00 {
				compatible = "atmel,sama5d3-rstc", "atmel,at91sam9g45-rstc";
				reg = <0xfffffe00 0x10>;
				clocks = <0x9>;
				phandle = <0xc2>;
			};

			shutdown-controller@fffffe10 {
				compatible = "atmel,at91sam9x5-shdwc";
				reg = <0xfffffe10 0x10>;
				clocks = <0x9>;
				phandle = <0xc3>;
			};

			timer@fffffe30 {
				compatible = "atmel,at91sam9260-pit";
				reg = <0xfffffe30 0xf>;
				interrupts = <0x3 0x4 0x5>;
				clocks = <0x3e>;
				phandle = <0xc4>;
			};

			watchdog@fffffe40 {
				compatible = "atmel,at91sam9260-wdt";
				reg = <0xfffffe40 0x10>;
				interrupts = <0x4 0x4 0x7>;
				clocks = <0x9>;
				atmel,watchdog-type = "hardware";
				atmel,reset-type = "all";
				atmel,dbg-halt;
				status = "disabled";
				phandle = <0xc5>;
			};

			sckc@fffffe50 {
				compatible = "atmel,at91sam9x5-sckc";
				reg = <0xfffffe50 0x4>;

				slow_rc_osc {
					compatible = "atmel,at91sam9x5-clk-slow-rc-osc";
					#clock-cells = <0x0>;
					clock-frequency = <0x8000>;
					clock-accuracy = <0x2faf080>;
					atmel,startup-time-usec = <0x4b>;
					phandle = <0x45>;
				};

				slow_osc {
					compatible = "atmel,at91sam9x5-clk-slow-osc";
					#clock-cells = <0x0>;
					clocks = <0x44>;
					atmel,startup-time-usec = <0x124f80>;
					phandle = <0x46>;
				};

				slowck {
					compatible = "atmel,at91sam9x5-clk-slow";
					#clock-cells = <0x0>;
					clocks = <0x45 0x46>;
					phandle = <0x9>;
				};
			};

			rtc@fffffeb0 {
				compatible = "atmel,at91rm9200-rtc";
				reg = <0xfffffeb0 0x30>;
				interrupts = <0x1 0x4 0x7>;
				clocks = <0x9>;
				status = "disabled";
			};

			ethernet@f0028000 {
				compatible = "atmel,sama5d3-gem";
				reg = <0xf0028000 0x100>;
				interrupts = <0x22 0x4 0x3>;
				pinctrl-names = "default";
				pinctrl-0 = <0x47 0x48>;
				clocks = <0x49 0x49>;
				clock-names = "hclk", "pclk";
				status = "okay";
				#address-cells = <0x1>;
				#size-cells = <0x0>;
				phy-mode = "rgmii";
				phandle = <0x7>;

				fixed-link {
					speed = <0x64>;
					full-duplex;
				};
			};

			ethernet@f802c000 {
				compatible = "atmel,sama5d3-macb", "cdns,at91sam9260-macb", "cdns,macb";
				reg = <0xf802c000 0x100>;
				interrupts = <0x23 0x4 0x3>;
				pinctrl-names = "default";
				pinctrl-0 = <0x4a>;
				clocks = <0x4b 0x4b>;
				clock-names = "hclk", "pclk";
				status = "okay";
				phy-mode = "rmii";
				#address-cells = <0x1>;
				#size-cells = <0x0>;
				phandle = <0xc6>;

				ethernet-phy@1 {
					reg = <0x1>;
				};
			};

			hlcdc@f0030000 {
				compatible = "atmel,sama5d3-hlcdc";
				reg = <0xf0030000 0x2000>;
				interrupts = <0x24 0x4 0x0>;
				clocks = <0x4c 0x4d 0x9>;
				clock-names = "periph_clk", "sys_clk", "slow_clk";
				status = "okay";
				phandle = <0xc7>;

				hlcdc-display-controller {
					compatible = "atmel,hlcdc-display-controller";
					#address-cells = <0x1>;
					#size-cells = <0x0>;
					pinctrl-names = "default";
					pinctrl-0 = <0x4e 0x4f>;

					port@0 {
						#address-cells = <0x1>;
						#size-cells = <0x0>;
						reg = <0x0>;

						endpoint@0 {
							reg = <0x0>;
							remote-endpoint = <0x50>;
							phandle = <0x69>;
						};
					};
				};

				hlcdc-pwm {
					compatible = "atmel,hlcdc-pwm";
					pinctrl-names = "default";
					pinctrl-0 = <0x51>;
					#pwm-cells = <0x3>;
					phandle = <0x65>;
				};
			};

			mmc@f8004000 {
				compatible = "atmel,hsmci";
				reg = <0xf8004000 0x600>;
				interrupts = <0x17 0x4 0x0>;
				dmas = <0x17 0x2 0x1>;
				dma-names = "rxtx";
				pinctrl-names = "default";
				pinctrl-0 = <0x52 0x53>;
				clocks = <0x54>;
				clock-names = "mci_clk";
				status = "disabled";
				#address-cells = <0x1>;
				#size-cells = <0x0>;
				phandle = <0xc8>;
			};

			timer@f8014000 {
				compatible = "atmel,at91sam9x5-tcb", "simple-mfd", "syscon";
				#address-cells = <0x1>;
				#size-cells = <0x0>;
				reg = <0xf8014000 0x100>;
				interrupts = <0x1b 0x4 0x0>;
				clocks = <0x55 0x9>;
				clock-names = "t0_clk", "slow_clk";
				phandle = <0xc9>;
			};

			serial@f8028000 {
				compatible = "atmel,at91sam9260-usart";
				reg = <0xf8028000 0x100>;
				interrupts = <0x11 0x4 0x5>;
				pinctrl-names = "default";
				pinctrl-0 = <0x56>;
				clocks = <0x57>;
				clock-names = "usart";
				status = "disabled";
				phandle = <0xca>;
			};
		};

		sram@200000 {
			compatible = "mmio-sram";
			no-memory-wc;
			reg = <0x200000 0x2400>;
			phandle = <0x61>;
		};

		gadget@500000 {
			#address-cells = <0x1>;
			#size-cells = <0x0>;
			compatible = "atmel,sama5d3-udc";
			reg = <0x500000 0x100000 0xf8030000 0x4000>;
			interrupts = <0x21 0x4 0x2>;
			clocks = <0x58 0x3d>;
			clock-names = "pclk", "hclk";
			status = "okay";
			atmel,vbus-gpio = <0xf 0x9 0x0>;
			pinctrl-names = "default";
			pinctrl-0 = <0x59>;
			phandle = <0xcb>;

			ep@0 {
				reg = <0x0>;
				atmel,fifo-size = <0x40>;
				atmel,nb-banks = <0x1>;
			};

			ep@1 {
				reg = <0x1>;
				atmel,fifo-size = <0x400>;
				atmel,nb-banks = <0x3>;
				atmel,can-dma;
				atmel,can-isoc;
			};

			ep@2 {
				reg = <0x2>;
				atmel,fifo-size = <0x400>;
				atmel,nb-banks = <0x3>;
				atmel,can-dma;
				atmel,can-isoc;
			};

			ep@3 {
				reg = <0x3>;
				atmel,fifo-size = <0x400>;
				atmel,nb-banks = <0x2>;
				atmel,can-dma;
			};

			ep@4 {
				reg = <0x4>;
				atmel,fifo-size = <0x400>;
				atmel,nb-banks = <0x2>;
				atmel,can-dma;
			};

			ep@5 {
				reg = <0x5>;
				atmel,fifo-size = <0x400>;
				atmel,nb-banks = <0x2>;
				atmel,can-dma;
			};

			ep@6 {
				reg = <0x6>;
				atmel,fifo-size = <0x400>;
				atmel,nb-banks = <0x2>;
				atmel,can-dma;
			};

			ep@7 {
				reg = <0x7>;
				atmel,fifo-size = <0x400>;
				atmel,nb-banks = <0x2>;
				atmel,can-dma;
			};

			ep@8 {
				reg = <0x8>;
				atmel,fifo-size = <0x400>;
				atmel,nb-banks = <0x2>;
			};

			ep@9 {
				reg = <0x9>;
				atmel,fifo-size = <0x400>;
				atmel,nb-banks = <0x2>;
			};

			ep@10 {
				reg = <0xa>;
				atmel,fifo-size = <0x400>;
				atmel,nb-banks = <0x2>;
			};

			ep@11 {
				reg = <0xb>;
				atmel,fifo-size = <0x400>;
				atmel,nb-banks = <0x2>;
			};

			ep@12 {
				reg = <0xc>;
				atmel,fifo-size = <0x400>;
				atmel,nb-banks = <0x2>;
			};

			ep@13 {
				reg = <0xd>;
				atmel,fifo-size = <0x400>;
				atmel,nb-banks = <0x2>;
			};

			ep@14 {
				reg = <0xe>;
				atmel,fifo-size = <0x400>;
				atmel,nb-banks = <0x2>;
			};

			ep@15 {
				reg = <0xf>;
				atmel,fifo-size = <0x400>;
				atmel,nb-banks = <0x2>;
			};
		};

		ohci@600000 {
			compatible = "atmel,at91rm9200-ohci", "usb-ohci";
			reg = <0x600000 0x100000>;
			interrupts = <0x20 0x4 0x2>;
			clocks = <0x5a 0x5a 0x5b>;
			clock-names = "ohci_clk", "hclk", "uhpck";
			status = "okay";
			num-ports = <0x3>;
			atmel,vbus-gpio = <0x0 0xf 0x3 0x1 0xf 0x4 0x1>;
			phandle = <0xcc>;
		};

		ehci@700000 {
			compatible = "atmel,at91sam9g45-ehci", "usb-ehci";
			reg = <0x700000 0x100000>;
			interrupts = <0x20 0x4 0x2>;
			clocks = <0x3d 0x5a>;
			clock-names = "usb_clk", "ehci_clk";
			status = "okay";
			phandle = <0xcd>;
		};

		ebi@10000000 {
			compatible = "atmel,sama5d3-ebi";
			#address-cells = <0x2>;
			#size-cells = <0x1>;
			atmel,smc = <0x5c>;
			reg = <0x10000000 0x10000000 0x40000000 0x30000000>;
			ranges = <0x0 0x0 0x10000000 0x10000000 0x1 0x0 0x40000000 0x10000000 0x2 0x0 0x50000000 0x10000000 0x3 0x0 0x60000000 0x10000000>;
			clocks = <0x3e>;
			status = "okay";
			pinctrl-0 = <0x5d 0x5e 0x5f 0x60>;
			pinctr-name = "default";
			phandle = <0xce>;

			nand-controller {
				compatible = "atmel,sama5d3-nand-controller";
				atmel,nfc-sram = <0x61>;
				atmel,nfc-io = <0x62>;
				ecc-engine = <0x63>;
				#address-cells = <0x2>;
				#size-cells = <0x1>;
				ranges;
				status = "okay";
				pinctrl-0 = <0x64>;
				pinctrl-names = "default";
				phandle = <0xcf>;

				nand@3 {
					reg = <0x3 0x0 0x800000>;
					atmel,rb = <0x0>;
					nand-bus-width = <0x8>;
					nand-ecc-mode = "hw";
					nand-ecc-strength = <0x8>;
					nand-ecc-step-size = <0x200>;
					nand-on-flash-bbt;
					label = "atmel_nand";

					partitions {
						compatible = "fixed-partitions";
						#address-cells = <0x1>;
						#size-cells = <0x1>;

						at91bootstrap@0 {
							label = "at91bootstrap";
							reg = <0x0 0x80000>;
						};

						bootloader@80000 {
							label = "bootloader";
							reg = <0x80000 0x100000>;
						};

						bootloaderenvred@180000 {
							label = "bootloader env redundant";
							reg = <0x180000 0x80000>;
						};

						bootloaderenv@200000 {
							label = "bootloader env";
							reg = <0x200000 0x80000>;
						};

						dtb@280000 {
							label = "device tree";
							reg = <0x280000 0x80000>;
						};

						kernel@300000 {
							label = "kernel";
							reg = <0x300000 0x600000>;
						};

						rootfs@800000 {
							label = "rootfs";
							reg = <0x900000 0x7f700000>;
						};
					};
				};
			};

			xrserial@0,0 {
				compatible = "exar,xr16l788";
				#address-cells = <0x1>;
				#size-cells = <0x1>;
				reg = <0x0 0x0 0x1000>;
				interrupt-parent = <0x5>;
				interrupts = <0x18 0x2>;
				status = "okay";
				atmel,smc-bus-width = <0x8>;
				atmel,smc-read-mode = "nrd";
				atmel,smc-write-mode = "nwe";
				atmel,smc-ncs-rd-setup-ns = <0xf>;
				atmel,smc-ncs-wr-setup-ns = <0xf>;
				atmel,smc-nwe-setup-ns = <0x2d>;
				atmel,smc-nrd-setup-ns = <0x2d>;
				atmel,smc-ncs-rd-pulse-ns = <0xd2>;
				atmel,smc-ncs-wr-pulse-ns = <0xd2>;
				atmel,smc-nrd-pulse-ns = <0xb4>;
				atmel,smc-nwe-pulse-ns = <0xb4>;
				atmel,smc-nrd-cycle-ns = <0xeb>;
				atmel,smc-nwe-cycle-ns = <0xeb>;
				atmel,smc-tdf-ns = <0x1e>;
				phandle = <0xd0>;
			};
		};

		nfc-io@70000000 {
			compatible = "atmel,sama5d3-nfc-io", "syscon";
			reg = <0x70000000 0x8000000>;
			phandle = <0x62>;
		};
	};

	backlight {
		compatible = "pwm-backlight";
		pwms = <0x65 0x0 0xc350 0x0>;
		brightness-levels = <0x0 0x4 0x8 0x10 0x20 0x40 0x80 0xff>;
		default-brightness-level = <0x7>;
		power-supply = <0x66>;
		status = "okay";
		enable-gpios = <0x5 0x1e 0x1>;
		phandle = <0x67>;
	};

	backlight_regulator {
		compatible = "regulator-fixed";
		regulator-name = "backlight-power-supply";
		regulator-min-microvolt = <0x4c4b40>;
		regulator-max-microvolt = <0x4c4b40>;
		status = "okay";
		phandle = <0x66>;
	};

	panel {
		compatible = "innolux,at070tn92", "simple-panel";
		backlight = <0x67>;
		power-supply = <0x68>;
		#address-cells = <0x1>;
		#size-cells = <0x0>;
		status = "okay";
		enable-gpios = <0x5 0x1d 0x1>;
		phandle = <0xd1>;

		port@0 {
			reg = <0x0>;
			#address-cells = <0x1>;
			#size-cells = <0x0>;

			endpoint@0 {
				reg = <0x0>;
				remote-endpoint = <0x69>;
				phandle = <0x50>;
			};
		};
	};

	panel_regulator {
		compatible = "regulator-fixed";
		regulator-name = "panel-power-supply";
		regulator-min-microvolt = <0x325aa0>;
		regulator-max-microvolt = <0x325aa0>;
		status = "okay";
		phandle = <0x68>;
	};

	gpio_keys {
		compatible = "gpio-keys";
		pinctrl-names = "default";
		pinctrl-0 = <0x6a>;

		home-key {
			label = "home-key";
			gpios = <0x6 0x19 0x1>;
			linux,code = <0x104>;
			wakeup-source;
		};
	};

	leds {
		compatible = "gpio-leds";

		system-status {
			label = "status";
			gpios = <0xf 0x17 0x1>;
			linux,default-trigger = "heartbeat";
		};
	};

	__symbols__ {
		slow_xtal = "/clocks/slow_xtal";
		main_xtal = "/clocks/main_xtal";
		adc_op_clk = "/clocks/adc_op_clk";
		sram = "/sram@300000";
		spi0 = "/ahb/apb/spi@f0004000";
		ksz8567 = "/ahb/apb/spi@f0004000/ksz8567@1";
		tcb0 = "/ahb/apb/timer@f0010000";
		timer0 = "/ahb/apb/timer@f0010000/timer@0";
		timer1 = "/ahb/apb/timer@f0010000/timer@1";
		i2c0 = "/ahb/apb/i2c@f0014000";
		i2c1 = "/ahb/apb/i2c@f0018000";
		ds3232 = "/ahb/apb/i2c@f0018000/rtc@68";
		pmic = "/ahb/apb/i2c@f0018000/act8865@5b";
		vcc_1v8_reg = "/ahb/apb/i2c@f0018000/act8865@5b/regulators/DCDC_REG1";
		vcc_1v2_reg = "/ahb/apb/i2c@f0018000/act8865@5b/regulators/DCDC_REG2";
		vcc_3v3_reg = "/ahb/apb/i2c@f0018000/act8865@5b/regulators/DCDC_REG3";
		vddfuse_reg = "/ahb/apb/i2c@f0018000/act8865@5b/regulators/LDO_REG1";
		vddana_reg = "/ahb/apb/i2c@f0018000/act8865@5b/regulators/LDO_REG2";
		usart0 = "/ahb/apb/serial@f001c000";
		uart0 = "/ahb/apb/serial@f0024000";
		pwm0 = "/ahb/apb/pwm@f002c000";
		isi = "/ahb/apb/isi@f0034000";
		sfr = "/ahb/apb/sfr@f0038000";
		mmc1 = "/ahb/apb/mmc@f8000000";
		spi1 = "/ahb/apb/spi@f8008000";
		i2c2 = "/ahb/apb/i2c@f801c000";
		usart2 = "/ahb/apb/serial@f8020000";
		usart3 = "/ahb/apb/serial@f8024000";
		hsmc = "/ahb/apb/hsmc@ffffc000";
		pmecc = "/ahb/apb/hsmc@ffffc000/ecc-engine@ffffc070";
		dma0 = "/ahb/apb/dma-controller@ffffe600";
		dma1 = "/ahb/apb/dma-controller@ffffe800";
		ramc0 = "/ahb/apb/ramc@ffffea00";
		dbgu = "/ahb/apb/serial@ffffee00";
		aic = "/ahb/apb/interrupt-controller@fffff000";
		pinctrl = "/ahb/apb/pinctrl@fffff200";
		pinctrl_adc0_adtrg = "/ahb/apb/pinctrl@fffff200/adc0/adc0_adtrg";
		pinctrl_adc0_ad0 = "/ahb/apb/pinctrl@fffff200/adc0/adc0_ad0";
		pinctrl_adc0_ad1 = "/ahb/apb/pinctrl@fffff200/adc0/adc0_ad1";
		pinctrl_adc0_ad2 = "/ahb/apb/pinctrl@fffff200/adc0/adc0_ad2";
		pinctrl_adc0_ad3 = "/ahb/apb/pinctrl@fffff200/adc0/adc0_ad3";
		pinctrl_adc0_ad4 = "/ahb/apb/pinctrl@fffff200/adc0/adc0_ad4";
		pinctrl_adc0_ad5 = "/ahb/apb/pinctrl@fffff200/adc0/adc0_ad5";
		pinctrl_adc0_ad6 = "/ahb/apb/pinctrl@fffff200/adc0/adc0_ad6";
		pinctrl_adc0_ad7 = "/ahb/apb/pinctrl@fffff200/adc0/adc0_ad7";
		pinctrl_adc0_ad8 = "/ahb/apb/pinctrl@fffff200/adc0/adc0_ad8";
		pinctrl_adc0_ad9 = "/ahb/apb/pinctrl@fffff200/adc0/adc0_ad9";
		pinctrl_adc0_ad10 = "/ahb/apb/pinctrl@fffff200/adc0/adc0_ad10";
		pinctrl_adc0_ad11 = "/ahb/apb/pinctrl@fffff200/adc0/adc0_ad11";
		pinctrl_dbgu = "/ahb/apb/pinctrl@fffff200/dbgu/dbgu-0";
		pinctrl_ebi_addr = "/ahb/apb/pinctrl@fffff200/ebi/ebi-addr-0";
		pinctrl_ebi_nand_addr = "/ahb/apb/pinctrl@fffff200/ebi/ebi-addr-1";
		pinctrl_ebi_uart_addr = "/ahb/apb/pinctrl@fffff200/ebi/ebi-addr-2";
		pinctrl_ebi_cs0 = "/ahb/apb/pinctrl@fffff200/ebi/ebi-cs0-0";
		pinctrl_ebi_cs1 = "/ahb/apb/pinctrl@fffff200/ebi/ebi-cs1-0";
		pinctrl_ebi_cs2 = "/ahb/apb/pinctrl@fffff200/ebi/ebi-cs2-0";
		pinctrl_ebi_nwait = "/ahb/apb/pinctrl@fffff200/ebi/ebi-nwait-0";
		pinctrl_ebi_nwr1_nbs1 = "/ahb/apb/pinctrl@fffff200/ebi/ebi-nwr1-nbs1-0";
		pinctrl_i2c0 = "/ahb/apb/pinctrl@fffff200/i2c0/i2c0-0";
		pinctrl_i2c1 = "/ahb/apb/pinctrl@fffff200/i2c1/i2c1-0";
		pinctrl_i2c2 = "/ahb/apb/pinctrl@fffff200/i2c2/i2c2-0";
		pinctrl_isi_data_0_7 = "/ahb/apb/pinctrl@fffff200/isi/isi-0-data-0-7";
		pinctrl_isi_data_8_9 = "/ahb/apb/pinctrl@fffff200/isi/isi-0-data-8-9";
		pinctrl_isi_data_10_11 = "/ahb/apb/pinctrl@fffff200/isi/isi-0-data-10-11";
		pinctrl_mmc1_clk_cmd_dat0 = "/ahb/apb/pinctrl@fffff200/mmc1/mmc1_clk_cmd_dat0";
		pinctrl_mmc1_dat1_3 = "/ahb/apb/pinctrl@fffff200/mmc1/mmc1_dat1_3";
		pinctrl_nand0_ale_cle = "/ahb/apb/pinctrl@fffff200/nand0/nand0_ale_cle-0";
		pinctrl_pwm0_pwmh0_0 = "/ahb/apb/pinctrl@fffff200/pwm0/pwm0_pwmh0-0";
		pinctrl_pwm0_pwmh0_1 = "/ahb/apb/pinctrl@fffff200/pwm0/pwm0_pwmh0-1";
		pinctrl_pwm0_pwml0_0 = "/ahb/apb/pinctrl@fffff200/pwm0/pwm0_pwml0-0";
		pinctrl_pwm0_pwml0_1 = "/ahb/apb/pinctrl@fffff200/pwm0/pwm0_pwml0-1";
		pinctrl_pwm0_pwmh1_0 = "/ahb/apb/pinctrl@fffff200/pwm0/pwm0_pwmh1-0";
		pinctrl_pwm0_pwmh1_1 = "/ahb/apb/pinctrl@fffff200/pwm0/pwm0_pwmh1-1";
		pinctrl_pwm0_pwmh1_2 = "/ahb/apb/pinctrl@fffff200/pwm0/pwm0_pwmh1-2";
		pinctrl_pwm0_pwml1_0 = "/ahb/apb/pinctrl@fffff200/pwm0/pwm0_pwml1-0";
		pinctrl_pwm0_pwml1_1 = "/ahb/apb/pinctrl@fffff200/pwm0/pwm0_pwml1-1";
		pinctrl_pwm0_pwml1_2 = "/ahb/apb/pinctrl@fffff200/pwm0/pwm0_pwml1-2";
		pinctrl_pwm0_pwmh2_0 = "/ahb/apb/pinctrl@fffff200/pwm0/pwm0_pwmh2-0";
		pinctrl_pwm0_pwmh2_1 = "/ahb/apb/pinctrl@fffff200/pwm0/pwm0_pwmh2-1";
		pinctrl_pwm0_pwml2_0 = "/ahb/apb/pinctrl@fffff200/pwm0/pwm0_pwml2-0";
		pinctrl_pwm0_pwml2_1 = "/ahb/apb/pinctrl@fffff200/pwm0/pwm0_pwml2-1";
		pinctrl_pwm0_pwmh3_0 = "/ahb/apb/pinctrl@fffff200/pwm0/pwm0_pwmh3-0";
		pinctrl_pwm0_pwmh3_1 = "/ahb/apb/pinctrl@fffff200/pwm0/pwm0_pwmh3-1";
		pinctrl_pwm0_pwml3_0 = "/ahb/apb/pinctrl@fffff200/pwm0/pwm0_pwml3-0";
		pinctrl_pwm0_pwml3_1 = "/ahb/apb/pinctrl@fffff200/pwm0/pwm0_pwml3-1";
		pinctrl_spi0 = "/ahb/apb/pinctrl@fffff200/spi0/spi0-0";
		pinctrl_spi1 = "/ahb/apb/pinctrl@fffff200/spi1/spi1-0";
		pinctrl_uart0 = "/ahb/apb/pinctrl@fffff200/uart0/uart0-0";
		pinctrl_uart1 = "/ahb/apb/pinctrl@fffff200/uart1/uart1-0";
		pinctrl_usart0 = "/ahb/apb/pinctrl@fffff200/usart0/usart0-0";
		pinctrl_usart0_rts_cts = "/ahb/apb/pinctrl@fffff200/usart0/usart0_rts_cts-0";
		pinctrl_usart2 = "/ahb/apb/pinctrl@fffff200/usart2/usart2-0";
		pinctrl_usart2_rts_cts = "/ahb/apb/pinctrl@fffff200/usart2/usart2_rts_cts-0";
		pinctrl_usart3 = "/ahb/apb/pinctrl@fffff200/usart3/usart3-0";
		pinctrl_usart3_rts_cts = "/ahb/apb/pinctrl@fffff200/usart3/usart3_rts_cts-0";
		pioA = "/ahb/apb/pinctrl@fffff200/gpio@fffff200";
		pioB = "/ahb/apb/pinctrl@fffff200/gpio@fffff400";
		pioC = "/ahb/apb/pinctrl@fffff200/gpio@fffff600";
		pioD = "/ahb/apb/pinctrl@fffff200/gpio@fffff800";
		pioE = "/ahb/apb/pinctrl@fffff200/gpio@fffffa00";
		pinctrl_macb0_data_rgmii = "/ahb/apb/pinctrl@fffff200/macb0/macb0_data_rgmii";
		pinctrl_macb0_data_gmii = "/ahb/apb/pinctrl@fffff200/macb0/macb0_data_gmii";
		pinctrl_macb0_signal_rgmii = "/ahb/apb/pinctrl@fffff200/macb0/macb0_signal_rgmii";
		pinctrl_macb0_signal_gmii = "/ahb/apb/pinctrl@fffff200/macb0/macb0_signal_gmii";
		pinctrl_macb1_rmii = "/ahb/apb/pinctrl@fffff200/macb1/macb1_rmii-0";
		pinctrl_lcd_base = "/ahb/apb/pinctrl@fffff200/lcd/lcd-base-0";
		pinctrl_lcd_pwm = "/ahb/apb/pinctrl@fffff200/lcd/lcd-pwm-0";
		pinctrl_lcd_rgb444 = "/ahb/apb/pinctrl@fffff200/lcd/lcd-rgb-0";
		pinctrl_lcd_rgb565 = "/ahb/apb/pinctrl@fffff200/lcd/lcd-rgb-1";
		pinctrl_lcd_rgb666 = "/ahb/apb/pinctrl@fffff200/lcd/lcd-rgb-2";
		pinctrl_lcd_rgb666_alt = "/ahb/apb/pinctrl@fffff200/lcd/lcd-rgb-2-alt";
		pinctrl_lcd_rgb888 = "/ahb/apb/pinctrl@fffff200/lcd/lcd-rgb-3";
		pinctrl_lcd_rgb888_alt = "/ahb/apb/pinctrl@fffff200/lcd/lcd-rgb-3-alt";
		pinctrl_mmc2_clk_cmd_dat0 = "/ahb/apb/pinctrl@fffff200/mmc2/mmc2_clk_cmd_dat0";
		pinctrl_mmc2_dat1_3 = "/ahb/apb/pinctrl@fffff200/mmc2/mmc2_dat1_3";
		pinctrl_lcd_ctp_int = "/ahb/apb/pinctrl@fffff200/board/lcd_ctp_int";
		pinctrl_i2c0_pu = "/ahb/apb/pinctrl@fffff200/board/i2c0_pu";
		pinctrl_i2c1_pu = "/ahb/apb/pinctrl@fffff200/board/i2c1_pu";
		pinctrl_i2c2_pu = "/ahb/apb/pinctrl@fffff200/board/i2c2_pu";
		pinctrl_key_gpio = "/ahb/apb/pinctrl@fffff200/board/key_gpio_0";
		pinctrl_mmc1_cd = "/ahb/apb/pinctrl@fffff200/board/mmc1_cd";
		pinctrl_usba_vbus = "/ahb/apb/pinctrl@fffff200/board/usba_vbus";
		pmc = "/ahb/apb/pmc@fffffc00";
		main_rc_osc = "/ahb/apb/pmc@fffffc00/main_rc_osc";
		main_osc = "/ahb/apb/pmc@fffffc00/main_osc";
		main = "/ahb/apb/pmc@fffffc00/mainck";
		plla = "/ahb/apb/pmc@fffffc00/pllack";
		plladiv = "/ahb/apb/pmc@fffffc00/plladivck";
		utmi = "/ahb/apb/pmc@fffffc00/utmick";
		mck = "/ahb/apb/pmc@fffffc00/masterck";
		usb = "/ahb/apb/pmc@fffffc00/usbck";
		prog = "/ahb/apb/pmc@fffffc00/progck";
		prog0 = "/ahb/apb/pmc@fffffc00/progck/prog0";
		prog1 = "/ahb/apb/pmc@fffffc00/progck/prog1";
		prog2 = "/ahb/apb/pmc@fffffc00/progck/prog2";
		smd = "/ahb/apb/pmc@fffffc00/smdclk";
		ddrck = "/ahb/apb/pmc@fffffc00/systemck/ddrck";
		smdck = "/ahb/apb/pmc@fffffc00/systemck/smdck";
		uhpck = "/ahb/apb/pmc@fffffc00/systemck/uhpck";
		udpck = "/ahb/apb/pmc@fffffc00/systemck/udpck";
		pck0 = "/ahb/apb/pmc@fffffc00/systemck/pck0";
		pck1 = "/ahb/apb/pmc@fffffc00/systemck/pck1";
		pck2 = "/ahb/apb/pmc@fffffc00/systemck/pck2";
		lcdck = "/ahb/apb/pmc@fffffc00/systemck/lcdck";
		dbgu_clk = "/ahb/apb/pmc@fffffc00/periphck/dbgu_clk";
		hsmc_clk = "/ahb/apb/pmc@fffffc00/periphck/hsmc_clk";
		pioA_clk = "/ahb/apb/pmc@fffffc00/periphck/pioA_clk";
		pioB_clk = "/ahb/apb/pmc@fffffc00/periphck/pioB_clk";
		pioC_clk = "/ahb/apb/pmc@fffffc00/periphck/pioC_clk";
		pioD_clk = "/ahb/apb/pmc@fffffc00/periphck/pioD_clk";
		pioE_clk = "/ahb/apb/pmc@fffffc00/periphck/pioE_clk";
		usart0_clk = "/ahb/apb/pmc@fffffc00/periphck/usart0_clk";
		usart2_clk = "/ahb/apb/pmc@fffffc00/periphck/usart2_clk";
		usart3_clk = "/ahb/apb/pmc@fffffc00/periphck/usart3_clk";
		uart0_clk = "/ahb/apb/pmc@fffffc00/periphck/uart0_clk";
		twi0_clk = "/ahb/apb/pmc@fffffc00/periphck/twi0_clk";
		twi1_clk = "/ahb/apb/pmc@fffffc00/periphck/twi1_clk";
		twi2_clk = "/ahb/apb/pmc@fffffc00/periphck/twi2_clk";
		mci1_clk = "/ahb/apb/pmc@fffffc00/periphck/mci1_clk";
		spi0_clk = "/ahb/apb/pmc@fffffc00/periphck/spi0_clk";
		spi1_clk = "/ahb/apb/pmc@fffffc00/periphck/spi1_clk";
		tcb0_clk = "/ahb/apb/pmc@fffffc00/periphck/tcb0_clk";
		pwm_clk = "/ahb/apb/pmc@fffffc00/periphck/pwm_clk";
		adc_clk = "/ahb/apb/pmc@fffffc00/periphck/adc_clk";
		dma0_clk = "/ahb/apb/pmc@fffffc00/periphck/dma0_clk";
		dma1_clk = "/ahb/apb/pmc@fffffc00/periphck/dma1_clk";
		uhphs_clk = "/ahb/apb/pmc@fffffc00/periphck/uhphs_clk";
		udphs_clk = "/ahb/apb/pmc@fffffc00/periphck/udphs_clk";
		isi_clk = "/ahb/apb/pmc@fffffc00/periphck/isi_clk";
		sha_clk = "/ahb/apb/pmc@fffffc00/periphck/sha_clk";
		aes_clk = "/ahb/apb/pmc@fffffc00/periphck/aes_clk";
		tdes_clk = "/ahb/apb/pmc@fffffc00/periphck/tdes_clk";
		trng_clk = "/ahb/apb/pmc@fffffc00/periphck/trng_clk";
		fuse_clk = "/ahb/apb/pmc@fffffc00/periphck/fuse_clk";
		mpddr_clk = "/ahb/apb/pmc@fffffc00/periphck/mpddr_clk";
		macb0_clk = "/ahb/apb/pmc@fffffc00/periphck/macb0_clk";
		macb1_clk = "/ahb/apb/pmc@fffffc00/periphck/macb1_clk";
		lcdc_clk = "/ahb/apb/pmc@fffffc00/periphck/lcdc_clk";
		mci2_clk = "/ahb/apb/pmc@fffffc00/periphck/mci2_clk";
		tcb1_clk = "/ahb/apb/pmc@fffffc00/periphck/tcb1_clk";
		uart1_clk = "/ahb/apb/pmc@fffffc00/periphck/uart1_clk";
		reset_controller = "/ahb/apb/rstc@fffffe00";
		shutdown_controller = "/ahb/apb/shutdown-controller@fffffe10";
		pit = "/ahb/apb/timer@fffffe30";
		watchdog = "/ahb/apb/watchdog@fffffe40";
		slow_rc_osc = "/ahb/apb/sckc@fffffe50/slow_rc_osc";
		slow_osc = "/ahb/apb/sckc@fffffe50/slow_osc";
		clk32k = "/ahb/apb/sckc@fffffe50/slowck";
		macb0 = "/ahb/apb/ethernet@f0028000";
		macb1 = "/ahb/apb/ethernet@f802c000";
		hlcdc = "/ahb/apb/hlcdc@f0030000";
		hlcdc_panel_output = "/ahb/apb/hlcdc@f0030000/hlcdc-display-controller/port@0/endpoint@0";
		hlcdc_pwm = "/ahb/apb/hlcdc@f0030000/hlcdc-pwm";
		mmc2 = "/ahb/apb/mmc@f8004000";
		tcb1 = "/ahb/apb/timer@f8014000";
		uart1 = "/ahb/apb/serial@f8028000";
		nfc_sram = "/ahb/sram@200000";
		usb0 = "/ahb/gadget@500000";
		usb1 = "/ahb/ohci@600000";
		usb2 = "/ahb/ehci@700000";
		ebi = "/ahb/ebi@10000000";
		nand_controller = "/ahb/ebi@10000000/nand-controller";
		xrserial1 = "/ahb/ebi@10000000/xrserial@0,0";
		nfc_io = "/ahb/nfc-io@70000000";
		backlight = "/backlight";
		bl_reg = "/backlight_regulator";
		panel = "/panel";
		panel_input = "/panel/port@0/endpoint@0";
		panel_reg = "/panel_regulator";
	};
};
